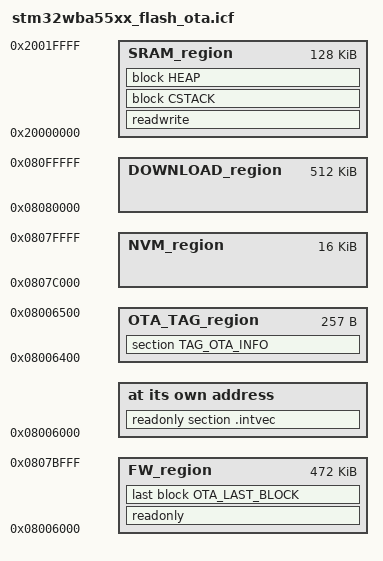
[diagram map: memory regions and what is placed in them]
/*###ICF### Section handled by ICF editor, don't touch! ****/
/*-Editor annotation file-*/
/* IcfEditorFile="$TOOLKIT_DIR$\config\ide\IcfEditor\cortex_v1_0.xml" */

/*-Sizes-*/
define symbol __ICFEDIT_size_cstack__       = 0x1000;
define symbol __ICFEDIT_size_heap__         = 0x10000;
define symbol __ICFEDIT_region_NVM_size__   = 0x4000;

/*-Memory Regions-*/
define symbol __ICFEDIT_region_DOWNLOAD_end__   = 0x080FFFFF;
define symbol __ICFEDIT_region_DOWNLOAD_start__ = 0x08080000;

define symbol __ICFEDIT_region_NVM_end__        = __ICFEDIT_region_DOWNLOAD_start__ - 0x1;
define symbol __ICFEDIT_region_NVM_start__      = __ICFEDIT_region_NVM_end__ - __ICFEDIT_region_NVM_size__ + 0x1;

define symbol __ICFEDIT_region_FW_end__         = __ICFEDIT_region_NVM_start__ - 0x1;
define symbol __ICFEDIT_region_FW_start__       = 0x08006000;

define symbol __region_SRAM_start__   = 0x20000000;
define symbol __region_SRAM_end__     = 0x2001FFFF;

/**** End of ICF editor section. ###ICF###*/

/*-Specials-*/
define symbol __ICFEDIT_intvec_start__ = __ICFEDIT_region_FW_start__;

define memory mem with size = 4G;
define region FW_region       = mem:[from __ICFEDIT_region_FW_start__       to __ICFEDIT_region_FW_end__];
define region NVM_region      = mem:[from __ICFEDIT_region_NVM_start__      to __ICFEDIT_region_NVM_end__];
define region DOWNLOAD_region = mem:[from __ICFEDIT_region_DOWNLOAD_start__ to __ICFEDIT_region_DOWNLOAD_end__];

define region SRAM_region     = mem:[from __region_SRAM_start__   to __region_SRAM_end__];
define region OTA_TAG_region  = mem:[from (__ICFEDIT_region_FW_start__ + 0x400) to (__ICFEDIT_region_FW_start__ + 0x400 + 0x100)];

define block CSTACK    with alignment = 8, size = __ICFEDIT_size_cstack__   { };
define block HEAP      with alignment = 8, size = __ICFEDIT_size_heap__     { };

initialize by copy { readwrite };
do not initialize  { section .noinit };

place at address mem:__ICFEDIT_intvec_start__ { readonly section .intvec };

keep { section TAG_OTA_INFO };
keep { section TAG_OTA_END };
keep { section .checksum };

define block OTA_LAST_BLOCK { section TAG_OTA_END, last section .checksum };

place in OTA_TAG_region     { section TAG_OTA_INFO };
place in FW_region          { readonly, last block OTA_LAST_BLOCK };
place in NVM_region         { };
place in DOWNLOAD_region    { };

place in SRAM_region        { readwrite, block CSTACK, block HEAP };
